# bao1x_peri register map
Vendor: baochip
Registers are 32-bit, read-write, reset 0x0 unless marked. A register's access mark holds for its fields unless they carry their own. Offsets are from the block's base; [hi:lo] are bit positions; {n}, {i} and the like mark numbered series; <NAME> marks a mode.

## UDMA_I2C_0
Base 0x50109000
Same registers: UDMA_I2C_1 0x5010A000, UDMA_I2C_2 0x5010B000, UDMA_I2C_3 0x5010C000
0x00 REG_RX_SADDR — See `udma_i2c_reg_if.sv <https://github.com/baochip/baochip-1x/blob/main/rtl/ips /udma/udma_i2c/rtl/udma_i2c_reg_if.sv>`__
  [11:0] r_rx_startaddr
0x04 REG_RX_SIZE — See `udma_i2c_reg_if.sv <https://github.com/baochip/baochip-1x/blob/main/rtl/ips /udma/udma_i2c/rtl/udma_i2c_reg_if.sv>`__
  [15:0] r_rx_size
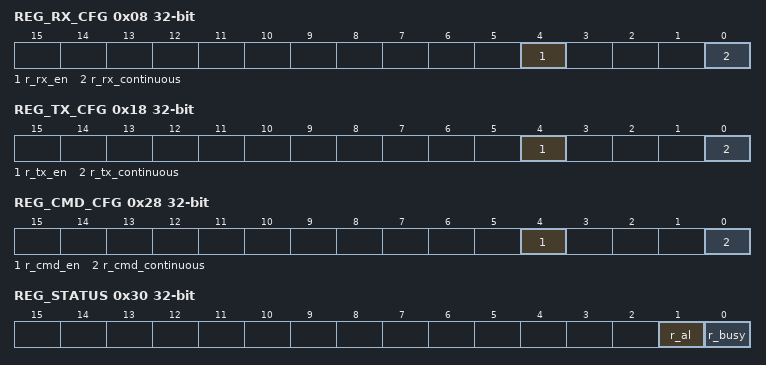
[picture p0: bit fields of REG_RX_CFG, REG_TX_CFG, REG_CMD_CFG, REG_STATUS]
0x08 REG_RX_CFG — See `udma_i2c_reg_if.sv <https://github.com/baochip/baochip-1x/blob/main/rtl/ips /udma/udma_i2c/rtl/udma_i2c_reg_if.sv>`__
  [4] r_rx_en, [0] r_rx_continuous
0x10 REG_TX_SADDR — See `udma_i2c_reg_if.sv <https://github.com/baochip/baochip-1x/blob/main/rtl/ips /udma/udma_i2c/rtl/udma_i2c_reg_if.sv>`__
  [11:0] r_tx_startaddr
0x14 REG_TX_SIZE — See `udma_i2c_reg_if.sv <https://github.com/baochip/baochip-1x/blob/main/rtl/ips /udma/udma_i2c/rtl/udma_i2c_reg_if.sv>`__
  [15:0] r_tx_size
0x18 REG_TX_CFG — See `udma_i2c_reg_if.sv <https://github.com/baochip/baochip-1x/blob/main/rtl/ips /udma/udma_i2c/rtl/udma_i2c_reg_if.sv>`__
  [4] r_tx_en, [0] r_tx_continuous
0x20 REG_CMD_SADDR — See `udma_i2c_reg_if.sv <https://github.com/baochip/baochip-1x/blob/main/rtl/ips /udma/udma_i2c/rtl/udma_i2c_reg_if.sv>`__
  [11:0] r_cmd_startaddr
0x24 REG_CMD_SIZE — See `udma_i2c_reg_if.sv <https://github.com/baochip/baochip-1x/blob/main/rtl/ips /udma/udma_i2c/rtl/udma_i2c_reg_if.sv>`__
  [15:0] r_cmd_size
0x28 REG_CMD_CFG — See `udma_i2c_reg_if.sv <https://github.com/baochip/baochip-1x/blob/main/rtl/ips /udma/udma_i2c/rtl/udma_i2c_reg_if.sv>`__
  [4] r_cmd_en, [0] r_cmd_continuous
0x30 REG_STATUS — See `udma_i2c_reg_if.sv <https://github.com/baochip/baochip-1x/blob/main/rtl/ips /udma/udma_i2c/rtl/udma_i2c_reg_if.sv>`__
  [1] r_al, [0] r_busy
0x38 REG_ACK — See `udma_i2c_reg_if.sv <https://github.com/baochip/baochip-1x/blob/main/rtl/ips /udma/udma_i2c/rtl/udma_i2c_reg_if.sv>`__
  [0] r_nack

## UDMA_SDIO
Base 0x5010D000
0x00 REG_RX_SADDR — See `udma_sdio_reg_if.sv <https://github.com/baochip/baochip-1x/blob/main/rtl/ip s/udma/udma_sdio/rtl/udma_sdio_reg_if.sv>`__
  [11:0] r_rx_startaddr
0x04 REG_RX_SIZE — See `udma_sdio_reg_if.sv <https://github.com/baochip/baochip-1x/blob/main/rtl/ip s/udma/udma_sdio/rtl/udma_sdio_reg_if.sv>`__
  [15:0] r_rx_size
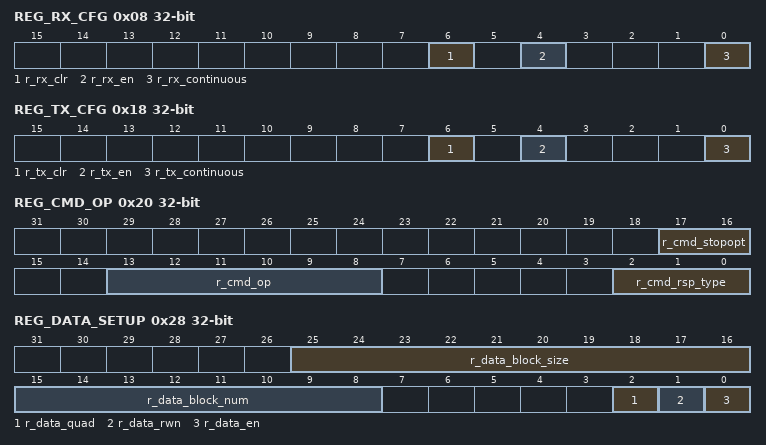
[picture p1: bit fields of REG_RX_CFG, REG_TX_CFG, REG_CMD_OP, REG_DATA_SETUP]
0x08 REG_RX_CFG — See `udma_sdio_reg_if.sv <https://github.com/baochip/baochip-1x/blob/main/rtl/ip s/udma/udma_sdio/rtl/udma_sdio_reg_if.sv>`__
  [6] r_rx_clr, [4] r_rx_en, [0] r_rx_continuous
0x10 REG_TX_SADDR — See `udma_sdio_reg_if.sv <https://github.com/baochip/baochip-1x/blob/main/rtl/ip s/udma/udma_sdio/rtl/udma_sdio_reg_if.sv>`__
  [11:0] r_tx_startaddr
0x14 REG_TX_SIZE — See `udma_sdio_reg_if.sv <https://github.com/baochip/baochip-1x/blob/main/rtl/ip s/udma/udma_sdio/rtl/udma_sdio_reg_if.sv>`__
  [15:0] r_tx_size
0x18 REG_TX_CFG — See `udma_sdio_reg_if.sv <https://github.com/baochip/baochip-1x/blob/main/rtl/ip s/udma/udma_sdio/rtl/udma_sdio_reg_if.sv>`__
  [6] r_tx_clr, [4] r_tx_en, [0] r_tx_continuous
0x20 REG_CMD_OP — See `udma_sdio_reg_if.sv <https://github.com/baochip/baochip-1x/blob/main/rtl/ip s/udma/udma_sdio/rtl/udma_sdio_reg_if.sv>`__
  [17:16] r_cmd_stopopt, [13:8] r_cmd_op, [2:0] r_cmd_rsp_type
0x28 REG_DATA_SETUP — See `udma_sdio_reg_if.sv <https://github.com/baochip/baochip-1x/blob/main/rtl/ip s/udma/udma_sdio/rtl/udma_sdio_reg_if.sv>`__
  [25:16] r_data_block_size, [15:8] r_data_block_num, [2] r_data_quad, [1] r_data_rwn, [0] r_data_en
0x2C REG_START — See `udma_sdio_reg_if.sv <https://github.com/baochip/baochip-1x/blob/main/rtl/ip s/udma/udma_sdio/rtl/udma_sdio_reg_if.sv>`__
  [0] r_sdio_start
{0x30+4i} REG_RSP{i} (i=0..3) — See `udma_sdio_reg_if.sv <https://github.com/baochip/baochip-1x/blob/main/rtl/ip s/udma/udma_sdio/rtl/udma_sdio_reg_if.sv>`__
  [31:0] cfg_rsp_data_i_{32i+31}_{32i}
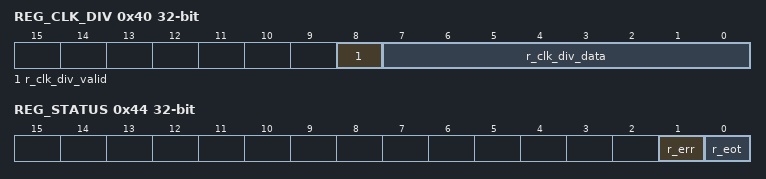
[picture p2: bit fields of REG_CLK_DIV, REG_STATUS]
0x40 REG_CLK_DIV — See `udma_sdio_reg_if.sv <https://github.com/baochip/baochip-1x/blob/main/rtl/ip s/udma/udma_sdio/rtl/udma_sdio_reg_if.sv>`__
  [8] r_clk_div_valid, [7:0] r_clk_div_data
0x44 REG_STATUS — See `udma_sdio_reg_if.sv <https://github.com/baochip/baochip-1x/blob/main/rtl/ip s/udma/udma_sdio/rtl/udma_sdio_reg_if.sv>`__
  [1] r_err, [0] r_eot
0x48 REG_DATA_TIMEOUT — See `udma_sdio_reg_if.sv <https://github.com/baochip/baochip-1x/blob/main/rtl/ip s/udma/udma_sdio/rtl/udma_sdio_reg_if.sv>`__
  [19:0] r_data_timeout
